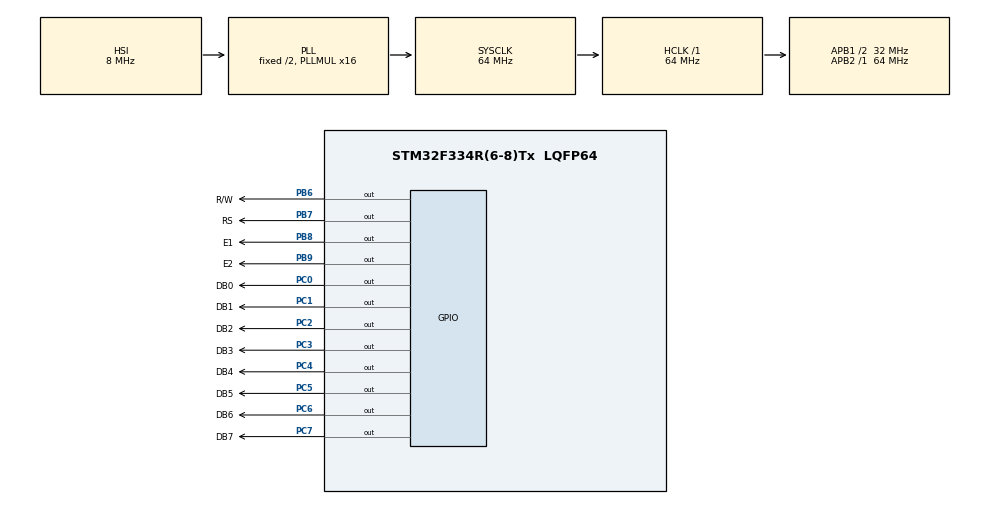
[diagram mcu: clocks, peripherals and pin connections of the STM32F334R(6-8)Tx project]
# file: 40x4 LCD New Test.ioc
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Mcu.Family=STM32F3
Mcu.Name=STM32F334R(6-8)Tx
Mcu.Package=LQFP64
NVIC.PriorityGroup=NVIC_PRIORITYGROUP_0
PB6.GPIO_Label=R/W
PB6.GPIO_ModeDefaultOutputPP=GPIO_MODE_OUTPUT_PP
PB6.GPIO_PuPd=GPIO_PULLUP
PB6.GPIO_Speed=GPIO_SPEED_FREQ_HIGH
PB6.PinState=GPIO_PIN_RESET
PB6.Signal=GPIO_Output
PB7.GPIO_Label=RS
PB7.GPIO_ModeDefaultOutputPP=GPIO_MODE_OUTPUT_PP
PB7.GPIO_PuPd=GPIO_PULLUP
PB7.GPIO_Speed=GPIO_SPEED_FREQ_HIGH
PB7.PinState=GPIO_PIN_RESET
PB7.Signal=GPIO_Output
PB8.GPIO_Label=E1
PB8.GPIO_ModeDefaultOutputPP=GPIO_MODE_OUTPUT_PP
PB8.GPIO_PuPd=GPIO_PULLUP
PB8.GPIO_Speed=GPIO_SPEED_FREQ_HIGH
PB8.PinState=GPIO_PIN_RESET
PB8.Signal=GPIO_Output
PB9.GPIO_Label=E2
PB9.GPIO_ModeDefaultOutputPP=GPIO_MODE_OUTPUT_PP
PB9.GPIO_PuPd=GPIO_PULLUP
PB9.GPIO_Speed=GPIO_SPEED_FREQ_HIGH
PB9.PinState=GPIO_PIN_RESET
PB9.Signal=GPIO_Output
PC0.GPIO_Label=DB0
PC0.GPIO_ModeDefaultOutputPP=GPIO_MODE_OUTPUT_PP
PC0.GPIO_PuPd=GPIO_PULLUP
PC0.GPIO_Speed=GPIO_SPEED_FREQ_HIGH
PC0.PinState=GPIO_PIN_RESET
PC0.Signal=GPIO_Output
PC1.GPIO_Label=DB1
PC1.GPIO_ModeDefaultOutputPP=GPIO_MODE_OUTPUT_PP
PC1.GPIO_PuPd=GPIO_PULLUP
PC1.GPIO_Speed=GPIO_SPEED_FREQ_HIGH
PC1.PinState=GPIO_PIN_RESET
PC1.Signal=GPIO_Output
PC2.GPIO_Label=DB2
PC2.GPIO_ModeDefaultOutputPP=GPIO_MODE_OUTPUT_PP
PC2.GPIO_PuPd=GPIO_PULLUP
PC2.GPIO_Speed=GPIO_SPEED_FREQ_HIGH
PC2.PinState=GPIO_PIN_RESET
PC2.Signal=GPIO_Output
PC3.GPIO_Label=DB3
PC3.GPIO_ModeDefaultOutputPP=GPIO_MODE_OUTPUT_PP
PC3.GPIO_PuPd=GPIO_PULLUP
PC3.GPIO_Speed=GPIO_SPEED_FREQ_HIGH
PC3.PinState=GPIO_PIN_RESET
PC3.Signal=GPIO_Output
PC4.GPIO_Label=DB4
PC4.GPIO_ModeDefaultOutputPP=GPIO_MODE_OUTPUT_PP
PC4.GPIO_PuPd=GPIO_PULLUP
PC4.GPIO_Speed=GPIO_SPEED_FREQ_HIGH
PC4.PinState=GPIO_PIN_RESET
PC4.Signal=GPIO_Output
PC5.GPIO_Label=DB5
PC5.GPIO_ModeDefaultOutputPP=GPIO_MODE_OUTPUT_PP
PC5.GPIO_PuPd=GPIO_PULLUP
PC5.GPIO_Speed=GPIO_SPEED_FREQ_HIGH
PC5.PinState=GPIO_PIN_RESET
PC5.Signal=GPIO_Output
PC6.GPIO_Label=DB6
PC6.GPIO_ModeDefaultOutputPP=GPIO_MODE_OUTPUT_PP
PC6.GPIO_PuPd=GPIO_PULLUP
PC6.GPIO_Speed=GPIO_SPEED_FREQ_HIGH
PC6.PinState=GPIO_PIN_RESET
PC6.Signal=GPIO_Output
PC7.GPIO_Label=DB7
PC7.GPIO_ModeDefaultOutputPP=GPIO_MODE_OUTPUT_PP
PC7.GPIO_PuPd=GPIO_PULLUP
PC7.GPIO_Speed=GPIO_SPEED_FREQ_HIGH
PC7.PinState=GPIO_PIN_RESET
PC7.Signal=GPIO_Output
PF0\ /\ OSC_IN.Mode=HSE-External-Oscillator
PF0\ /\ OSC_IN.Signal=RCC_OSC_IN
PF1\ /\ OSC_OUT.Mode=HSE-External-Oscillator
PF1\ /\ OSC_OUT.Signal=RCC_OSC_OUT
ProjectManager.HeapSize=0x200
ProjectManager.StackSize=0x400
ProjectManager.TargetToolchain=MDK-ARM V5
RCC.AHBFreq_Value=64000000
RCC.APB1CLKDivider=RCC_HCLK_DIV2
RCC.APB1Freq_Value=32000000
RCC.APB1TimFreq_Value=64000000
RCC.APB2Freq_Value=64000000
RCC.APB2TimFreq_Value=64000000
RCC.CortexFreq_Value=64000000
RCC.FLatency-AdvancedSettings=FLASH_LATENCY_2
RCC.HCLKFreq_Value=64000000
RCC.HSE_VALUE=8000000
RCC.HSI_VALUE=8000000
RCC.LSE_VALUE=32768
RCC.PLLMUL=RCC_PLL_MUL16
RCC.SYSCLKFreq_VALUE=64000000
RCC.SYSCLKSourceVirtual=RCC_SYSCLKSOURCE_PLLCLK
board=NUCLEO-F334R8

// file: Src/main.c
/**
  ******************************************************************************
  * File Name          : main.c
  * Description        : Main program body
  ******************************************************************************
  *
  * COPYRIGHT(c) 2016 STMicroelectronics
  *
  * Redistribution and use in source and binary forms, with or without modification,
  * are permitted provided that the following conditions are met:
  *   1. Redistributions of source code must retain the above copyright notice,
  *      this list of conditions and the following disclaimer.
  *   2. Redistributions in binary form must reproduce the above copyright notice,
  *      this list of conditions and the following disclaimer in the documentation
  *      and/or other materials provided with the distribution.
  *   3. Neither the name of STMicroelectronics nor the names of its contributors
  *      may be used to endorse or promote products derived from this software
  *      without specific prior written permission.
  *
  * THIS SOFTWARE IS PROVIDED BY THE COPYRIGHT HOLDERS AND CONTRIBUTORS "AS IS"
  * AND ANY EXPRESS OR IMPLIED WARRANTIES, INCLUDING, BUT NOT LIMITED TO, THE
  * IMPLIED WARRANTIES OF MERCHANTABILITY AND FITNESS FOR A PARTICULAR PURPOSE ARE
  * DISCLAIMED. IN NO EVENT SHALL THE COPYRIGHT HOLDER OR CONTRIBUTORS BE LIABLE
  * FOR ANY DIRECT, INDIRECT, INCIDENTAL, SPECIAL, EXEMPLARY, OR CONSEQUENTIAL
  * DAMAGES (INCLUDING, BUT NOT LIMITED TO, PROCUREMENT OF SUBSTITUTE GOODS OR
  * SERVICES; LOSS OF USE, DATA, OR PROFITS; OR BUSINESS INTERRUPTION) HOWEVER
  * CAUSED AND ON ANY THEORY OF LIABILITY, WHETHER IN CONTRACT, STRICT LIABILITY,
  * OR TORT (INCLUDING NEGLIGENCE OR OTHERWISE) ARISING IN ANY WAY OUT OF THE USE
  * OF THIS SOFTWARE, EVEN IF ADVISED OF THE POSSIBILITY OF SUCH DAMAGE.
  *
  ******************************************************************************
  */
#include "main.h"
#include "stm32f3xx_hal.h"

/* USER CODE BEGIN Includes */
#include "LCD.h"
/* USER CODE END Includes */

/* USER CODE BEGIN PV */
/* Private variables ---------------------------------------------------------*/

/* USER CODE END PV */

void SystemClock_Config(void);
void Error_Handler(void);
static void MX_GPIO_Init(void);

/* USER CODE BEGIN PFP */
/* Private function prototypes -----------------------------------------------*/

/* USER CODE END PFP */

int main(void)
{

  /* USER CODE BEGIN 1 */
//	unsigned int count=0;
	uint8_t st1[]="Hello";
	uint8_t st2[]="World";
	uint8_t st3[]="This is a 40x4 LCD";
	uint8_t st4[]="STM32F334 Microcontroller";
  /* USER CODE END 1 */

  /* MCU Configuration----------------------------------------------------------*/

  /* Reset of all peripherals, Initializes the Flash interface and the Systick. */
  HAL_Init();

  /* Configure the system clock */
  SystemClock_Config();

  /* Initialize all configured peripherals */
  MX_GPIO_Init();

  /* USER CODE BEGIN 2 */
	lcd_init();
  /* USER CODE END 2 */

  /* Infinite loop */
  while (1)
  {

  /* USER CODE BEGIN 3 */
		lcd_put_string(1, 0, st1);
		delay(5);
		lcd_put_string(2, 0, st2);
		delay(5);
		lcd_put_string(3, 0, st3);
		delay(5);
		lcd_put_string(4, 0, st4);
		delay(5);
  }
  /* USER CODE END 3 */

}

/** System Clock Configuration
*/
void SystemClock_Config(void)
{

  RCC_OscInitTypeDef RCC_OscInitStruct;
  RCC_ClkInitTypeDef RCC_ClkInitStruct;

    /**Initializes the CPU, AHB and APB busses clocks
    */
  RCC_OscInitStruct.OscillatorType = RCC_OSCILLATORTYPE_HSI;
  RCC_OscInitStruct.HSIState = RCC_HSI_ON;
  RCC_OscInitStruct.HSICalibrationValue = 16;
  RCC_OscInitStruct.PLL.PLLState = RCC_PLL_ON;
  RCC_OscInitStruct.PLL.PLLSource = RCC_PLLSOURCE_HSI;
  RCC_OscInitStruct.PLL.PLLMUL = RCC_PLL_MUL16;
  if (HAL_RCC_OscConfig(&RCC_OscInitStruct) != HAL_OK)
  {
    Error_Handler();
  }

    /**Initializes the CPU, AHB and APB busses clocks
    */
  RCC_ClkInitStruct.ClockType = RCC_CLOCKTYPE_HCLK|RCC_CLOCKTYPE_SYSCLK
                              |RCC_CLOCKTYPE_PCLK1|RCC_CLOCKTYPE_PCLK2;
  RCC_ClkInitStruct.SYSCLKSource = RCC_SYSCLKSOURCE_PLLCLK;
  RCC_ClkInitStruct.AHBCLKDivider = RCC_SYSCLK_DIV1;
  RCC_ClkInitStruct.APB1CLKDivider = RCC_HCLK_DIV2;
  RCC_ClkInitStruct.APB2CLKDivider = RCC_HCLK_DIV1;

  if (HAL_RCC_ClockConfig(&RCC_ClkInitStruct, FLASH_LATENCY_2) != HAL_OK)
  {
    Error_Handler();
  }

    /**Configure the Systick interrupt time
    */
  HAL_SYSTICK_Config(HAL_RCC_GetHCLKFreq()/1000);

    /**Configure the Systick
    */
  HAL_SYSTICK_CLKSourceConfig(SYSTICK_CLKSOURCE_HCLK);

  /* SysTick_IRQn interrupt configuration */
  HAL_NVIC_SetPriority(SysTick_IRQn, 0, 0);
}

/** Configure pins as
        * Analog
        * Input
        * Output
        * EVENT_OUT
        * EXTI
*/
static void MX_GPIO_Init(void)
{

  GPIO_InitTypeDef GPIO_InitStruct;

  /* GPIO Ports Clock Enable */
  __HAL_RCC_GPIOF_CLK_ENABLE();
  __HAL_RCC_GPIOC_CLK_ENABLE();
  __HAL_RCC_GPIOB_CLK_ENABLE();

  /*Configure GPIO pin Output Level */
  HAL_GPIO_WritePin(GPIOC, DB0_Pin|DB1_Pin|DB2_Pin|DB3_Pin
                          |DB4_Pin|DB5_Pin|DB6_Pin|DB7_Pin, GPIO_PIN_RESET);

  /*Configure GPIO pin Output Level */
  HAL_GPIO_WritePin(GPIOB, R_W_Pin|RS_Pin|E1_Pin|E2_Pin, GPIO_PIN_RESET);

  /*Configure GPIO pins : DB0_Pin DB1_Pin DB2_Pin DB3_Pin
                           DB4_Pin DB5_Pin DB6_Pin DB7_Pin */
  GPIO_InitStruct.Pin = DB0_Pin|DB1_Pin|DB2_Pin|DB3_Pin
                          |DB4_Pin|DB5_Pin|DB6_Pin|DB7_Pin;
  GPIO_InitStruct.Mode = GPIO_MODE_OUTPUT_PP;
  GPIO_InitStruct.Pull = GPIO_PULLUP;
  GPIO_InitStruct.Speed = GPIO_SPEED_FREQ_HIGH;
  HAL_GPIO_Init(GPIOC, &GPIO_InitStruct);

  /*Configure GPIO pins : R_W_Pin RS_Pin E1_Pin E2_Pin */
  GPIO_InitStruct.Pin = R_W_Pin|RS_Pin|E1_Pin|E2_Pin;
  GPIO_InitStruct.Mode = GPIO_MODE_OUTPUT_PP;
  GPIO_InitStruct.Pull = GPIO_PULLUP;
  GPIO_InitStruct.Speed = GPIO_SPEED_FREQ_HIGH;
  HAL_GPIO_Init(GPIOB, &GPIO_InitStruct);

}

void Error_Handler(void)
{
  while(1)
  {
  }
}

/************************ (C) COPYRIGHT STMicroelectronics *****END OF FILE****/
